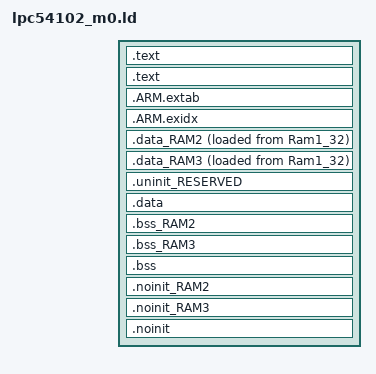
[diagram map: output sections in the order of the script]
/*
 * GENERATED FILE - DO NOT EDIT
 * (c) Code Red Technologies Ltd, 2008-2013
 * (c) NXP Semiconductors 2013-2016
 * Generated linker script file for LPC54102J512-M0
 * Created from linkscript.ldt by FMCreateLinkLibraries
 * Using Freemarker v2.3.23
 * LPCXpresso v8.0.0 [Build 526] [2015-11-23]  on Feb 18, 2016 5:00:41 PM
 */

ENTRY(ResetISR)

SECTIONS
{
    /* MAIN TEXT SECTION */
    .text : ALIGN(4)
    {
        FILL(0xff)
        __vectors_start__ = ABSOLUTE(.) ;
        KEEP(*(.isr_vector))
        /* Global Section Table */
        . = ALIGN(4) ; 
        __section_table_start = .;
        __data_section_table = .;
        LONG(LOADADDR(.data));
        LONG(    ADDR(.data));
        LONG(  SIZEOF(.data));
        LONG(LOADADDR(.data_RAM2));
        LONG(    ADDR(.data_RAM2));
        LONG(  SIZEOF(.data_RAM2));
        LONG(LOADADDR(.data_RAM3));
        LONG(    ADDR(.data_RAM3));
        LONG(  SIZEOF(.data_RAM3));
        __data_section_table_end = .;
        __bss_section_table = .;
        LONG(    ADDR(.bss));
        LONG(  SIZEOF(.bss));
        LONG(    ADDR(.bss_RAM2));
        LONG(  SIZEOF(.bss_RAM2));
        LONG(    ADDR(.bss_RAM3));
        LONG(  SIZEOF(.bss_RAM3));
        __bss_section_table_end = .;
        __section_table_end = . ;
	    /* End of Global Section Table */

        *(.after_vectors*)

    } >Ram1_32

    .text : ALIGN(4)    
    {
        *(.text*)
        *(.rodata .rodata.* .constdata .constdata.*)
        . = ALIGN(4);
    } > Ram1_32
    /*
     * for exception handling/unwind - some Newlib functions (in common
     * with C++ and STDC++) use this. 
     */
    .ARM.extab : ALIGN(4) 
    {
        *(.ARM.extab* .gnu.linkonce.armextab.*)
    } > Ram1_32
    __exidx_start = .;

    .ARM.exidx : ALIGN(4)
    {
        *(.ARM.exidx* .gnu.linkonce.armexidx.*)
    } > Ram1_32
    __exidx_end = .;

    _etext = .;
        
    /* DATA section for Ram0_64 */
    .data_RAM2 : ALIGN(4)
    {
        FILL(0xff)
        PROVIDE(__start_data_RAM2 = .) ;
        *(.ramfunc.$RAM2)
        *(.ramfunc.$Ram0_64)
        *(.data.$RAM2*)
        *(.data.$Ram0_64*)
        . = ALIGN(4) ;
        PROVIDE(__end_data_RAM2 = .) ;
     } > Ram0_64 AT>Ram1_32

    /* DATA section for Ram2_8 */
    .data_RAM3 : ALIGN(4)
    {
        FILL(0xff)
        PROVIDE(__start_data_RAM3 = .) ;
        *(.ramfunc.$RAM3)
        *(.ramfunc.$Ram2_8)
        *(.data.$RAM3*)
        *(.data.$Ram2_8*)
        . = ALIGN(4) ;
        PROVIDE(__end_data_RAM3 = .) ;
     } > Ram2_8 AT>Ram1_32

    /* MAIN DATA SECTION */
    .uninit_RESERVED : ALIGN(4)
    {
        KEEP(*(.bss.$RESERVED*))
        . = ALIGN(4) ;
        _end_uninit_RESERVED = .;
    } > Ram1_32
    /* Main DATA section (Ram1_32) */
    .data : ALIGN(4)
    {
       FILL(0xff)
       _data = . ;
       *(vtable)
       *(.ramfunc*)
       *(.data*)
       . = ALIGN(4) ;
       _edata = . ;
    } > Ram1_32 AT>Ram1_32
    /* BSS section for Ram0_64 */
    .bss_RAM2 : ALIGN(4)
    {
       PROVIDE(__start_bss_RAM2 = .) ;
       *(.bss.$RAM2*)
       *(.bss.$Ram0_64*)
       . = ALIGN (. != 0 ? 4 : 1) ; /* avoid empty segment */
       PROVIDE(__end_bss_RAM2 = .) ;
    } > Ram0_64 
    /* BSS section for Ram2_8 */
    .bss_RAM3 : ALIGN(4)
    {
       PROVIDE(__start_bss_RAM3 = .) ;
       *(.bss.$RAM3*)
       *(.bss.$Ram2_8*)
       . = ALIGN (. != 0 ? 4 : 1) ; /* avoid empty segment */
       PROVIDE(__end_bss_RAM3 = .) ;
    } > Ram2_8 
    /* MAIN BSS SECTION */
    .bss : ALIGN(4)
    {
        _bss = .;
        *(.bss*)
        *(COMMON)
        . = ALIGN(4) ;
        _ebss = .;
        PROVIDE(end = .);
    } > Ram1_32
    /* NOINIT section for Ram0_64 */
    .noinit_RAM2 (NOLOAD) : ALIGN(4)
    {
       *(.noinit.$RAM2*)
       *(.noinit.$Ram0_64*)
       . = ALIGN(4) ;
    } > Ram0_64 
    /* NOINIT section for Ram2_8 */
    .noinit_RAM3 (NOLOAD) : ALIGN(4)
    {
       *(.noinit.$RAM3*)
       *(.noinit.$Ram2_8*)
       . = ALIGN(4) ;
    } > Ram2_8 
    /* DEFAULT NOINIT SECTION */
    .noinit (NOLOAD): ALIGN(4)
    {
        _noinit = .;
        *(.noinit*) 
         . = ALIGN(4) ;
        _end_noinit = .;
    } > Ram1_32

    PROVIDE(_pvHeapStart = DEFINED(__user_heap_base) ? __user_heap_base : .);
    PROVIDE(_vStackTop = DEFINED(__user_stack_top) ? __user_stack_top : __top_Ram1_32 - 0);
}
